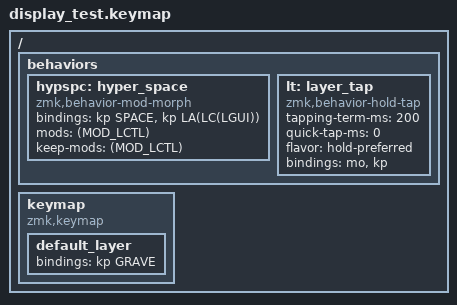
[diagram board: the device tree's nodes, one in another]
/*
 * Copyright (c) 2021 The ZMK Contributors
 *
 * SPDX-License-Identifier: MIT
 */

#include <behaviors.dtsi>
#include <dt-bindings/zmk/keys.h>
#include <dt-bindings/zmk/outputs.h>


/ {
    behaviors {
        hypspc: hyper_space {
            compatible = "zmk,behavior-mod-morph";
            #binding-cells = <0>;
            bindings = <&kp SPACE>, <&kp LA(LC(LGUI))>;
            mods = <(MOD_LCTL)>;
            keep-mods = <(MOD_LCTL)>;
        };
        // Make layer tap hold-preferred.
        lt: layer_tap {
            compatible = "zmk,behavior-hold-tap";
            #binding-cells = <2>;
            tapping-term-ms = <200>;
            quick-tap-ms = <0>;
            flavor = "hold-preferred";
            bindings = <&mo>, <&kp>;
        };
    };
    keymap {
        compatible = "zmk,keymap";

        default_layer {
            /*
            * ┌───┬───┬───┬───┬───┬───┐                    ┌───┬───┬───┬───┬───┬───┐
            * │ ` │ 1 │ 2 │ 3 │ 4 │ 5 │                    │ 7 │ 7 │ 8 │ 9 │ 0 │ - │
            * ├───┼───┼───┼───┼───┼───┤                    ├───┼───┼───┼───┼───┼───┤
            * │ > │ q │ w │ e │ r │ t │                    │ y │ u │ i │ o │ p │ * │
            * ├───┼───┼───┼───┼───┼───┤                    ├───┼───┼───┼───┼───┼───┤
            * │ ^ │ a │ s │ d │ f │ g │                    │ h │ j │ k │ l │ ; │ ' │
            * ├───┼───┼───┼───┼───┼───┤                    ├───┼───┼───┼───┼───┼───┤
            * │ s │ z │ x │ c │ v │ h │                    │ n │ m │ , │ . │ / │ s │
            * └───┴───┼───┼───┼───┼───┼───┬───┐    ┌───┬───┼───┼───┼───┼───┼───┴───┘
            *         │ x │ x │ x │   │ x │ x │    │ x │ x │   │ x │ x │ x │
            *         └───┴───┴───┘   └───┴───┘    └───┴───┘   └───┴───┴───┘
            */
            bindings = <
                &kp GRAVE
            >;
        };
    };
};
